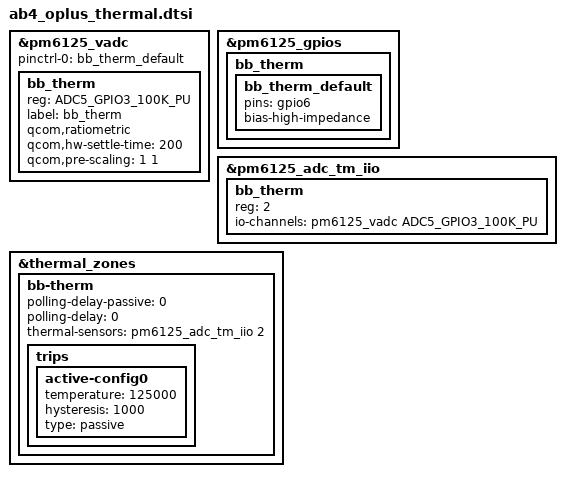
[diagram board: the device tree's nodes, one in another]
&pm6125_vadc {
	pinctrl-0 =  <&bb_therm_default>;

	bb_therm {
		reg = <ADC5_GPIO3_100K_PU>;
		label = "bb_therm";
		qcom,ratiometric;
		qcom,hw-settle-time = <200>;
		qcom,pre-scaling = <1 1>;
	};

};

&pm6125_gpios {
	bb_therm {
		bb_therm_default: bb_therm_default {
			pins = "gpio6";
			bias-high-impedance;
		};
	};
};

&pm6125_adc_tm_iio{
				bb_therm {
				reg = <2>;
				io-channels = <&pm6125_vadc ADC5_GPIO3_100K_PU>;
			};
};

&thermal_zones {
	bb-therm {
	polling-delay-passive = <0>;
	polling-delay = <0>;
	thermal-sensors = <&pm6125_adc_tm_iio 2>;
	trips {
		active-config0 {
		temperature = <125000>;
		hysteresis = <1000>;
		type = "passive";
					};
		};
	};
};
